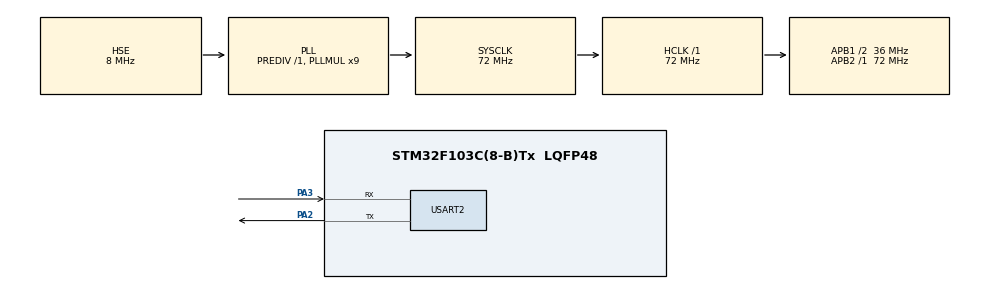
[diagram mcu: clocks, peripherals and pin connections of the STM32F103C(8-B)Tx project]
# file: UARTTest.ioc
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Dma.Request0=USART2_TX
Dma.Request1=USART2_RX
Dma.USART2_RX.1.Direction=DMA_PERIPH_TO_MEMORY
Dma.USART2_RX.1.Instance=DMA1_Channel6
Dma.USART2_RX.1.MemDataAlignment=DMA_MDATAALIGN_BYTE
Dma.USART2_RX.1.MemInc=DMA_MINC_ENABLE
Dma.USART2_RX.1.Mode=DMA_CIRCULAR
Dma.USART2_RX.1.PeriphDataAlignment=DMA_PDATAALIGN_BYTE
Dma.USART2_RX.1.PeriphInc=DMA_PINC_DISABLE
Dma.USART2_RX.1.Priority=DMA_PRIORITY_LOW
Dma.USART2_TX.0.Direction=DMA_MEMORY_TO_PERIPH
Dma.USART2_TX.0.Instance=DMA1_Channel7
Dma.USART2_TX.0.MemDataAlignment=DMA_MDATAALIGN_BYTE
Dma.USART2_TX.0.MemInc=DMA_MINC_ENABLE
Dma.USART2_TX.0.Mode=DMA_NORMAL
Dma.USART2_TX.0.PeriphDataAlignment=DMA_PDATAALIGN_BYTE
Dma.USART2_TX.0.PeriphInc=DMA_PINC_DISABLE
Dma.USART2_TX.0.Priority=DMA_PRIORITY_LOW
Mcu.Family=STM32F1
Mcu.Name=STM32F103C(8-B)Tx
Mcu.Package=LQFP48
NVIC.DMA1_Channel6_IRQn=true\:0\:0\:false\:false\:true\:false\:true
NVIC.DMA1_Channel7_IRQn=true\:0\:0\:false\:false\:true\:false\:true
NVIC.PriorityGroup=NVIC_PRIORITYGROUP_4
NVIC.USART2_IRQn=true\:0\:0\:false\:false\:true\:true\:true
PA13.Mode=Serial_Wire
PA13.Signal=SYS_JTMS-SWDIO
PA14.Mode=Serial_Wire
PA14.Signal=SYS_JTCK-SWCLK
PA2.Mode=Asynchronous
PA2.Signal=USART2_TX
PA3.Mode=Asynchronous
PA3.Signal=USART2_RX
PD0-OSC_IN.Mode=HSE-External-Oscillator
PD0-OSC_IN.Signal=RCC_OSC_IN
PD1-OSC_OUT.Mode=HSE-External-Oscillator
PD1-OSC_OUT.Signal=RCC_OSC_OUT
ProjectManager.HeapSize=0x200
ProjectManager.StackSize=0x400
ProjectManager.TargetToolchain=MDK-ARM V5.27
RCC.AHBFreq_Value=72000000
RCC.APB1CLKDivider=RCC_HCLK_DIV2
RCC.APB1Freq_Value=36000000
RCC.APB1TimFreq_Value=72000000
RCC.APB2Freq_Value=72000000
RCC.APB2TimFreq_Value=72000000
RCC.HCLKFreq_Value=72000000
RCC.PLLMUL=RCC_PLL_MUL9
RCC.PLLSourceVirtual=RCC_PLLSOURCE_HSE
RCC.SYSCLKFreq_VALUE=72000000
RCC.SYSCLKSource=RCC_SYSCLKSOURCE_PLLCLK
RCC.USBFreq_Value=72000000
USART2.VirtualMode=VM_ASYNC
board=custom

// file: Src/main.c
/* USER CODE BEGIN Header */
/**
  ******************************************************************************
  * @file           : main.c
  * @brief          : Main program body
  ******************************************************************************
  * @attention
  *
  * <h2><center>&copy; Copyright (c) 2020 STMicroelectronics.
  * All rights reserved.</center></h2>
  *
  * This software component is licensed by ST under BSD 3-Clause license,
  * the "License"; You may not use this file except in compliance with the
  * License. You may obtain a copy of the License at:
  *                        opensource.org/licenses/BSD-3-Clause
  *
  ******************************************************************************
  */
/* USER CODE END Header */

#include "main.h"
#include "dma.h"
#include "usart.h"
#include "gpio.h"

void SystemClock_Config(void);

/* USER CODE BEGIN 0 */
#define BUFFER_SIZE 200
uint8_t Buffer[BUFFER_SIZE];
volatile uint32_t BufPtrIn = 0, BufPtrOut = 0;

//void HAL_UART_RxCpltCallback(UART_HandleTypeDef *huart)
//{
//	if (huart == &huart2)
//	{
//		BufPtrIn++;
//		if (BufPtrIn == BUFFER_SIZE)
//			BufPtrIn = 0;
//		HAL_UART_Receive_IT(&huart2, &Buffer[BufPtrIn], 1);
//	}
//}

void HAL_SYSTICK_Callback(void)
{
	BufPtrIn = BUFFER_SIZE - huart2.hdmarx->Instance->CNDTR;

	if (HAL_GetTick() % 5 != 0)
		return;

	uint32_t buffsize;

	if (BufPtrOut != BufPtrIn)
	{
		if (BufPtrOut > BufPtrIn) // Rollback
			buffsize = BUFFER_SIZE - BufPtrOut;
		else
			buffsize = BufPtrIn - BufPtrOut;

//		if (HAL_UART_Transmit_IT(&huart2, &Buffer[BufPtrOut], buffsize) == HAL_OK)
		if (HAL_UART_Transmit_DMA(&huart2, &Buffer[BufPtrOut], buffsize) == HAL_OK)
		{
			BufPtrOut += buffsize;
			if (BufPtrOut == BUFFER_SIZE)
				BufPtrOut = 0;
		}
	}
}

#include "stdio.h"
int fputc(int ch, FILE* f)
{
	HAL_UART_Transmit(&huart2, (uint8_t *)&ch, 1, 100);
	return ch;
}
/* USER CODE END 0 */

int main(void)
{

  /* MCU Configuration--------------------------------------------------------*/

  /* Reset of all peripherals, Initializes the Flash interface and the Systick. */
  HAL_Init();

  /* Configure the system clock */
  SystemClock_Config();

  /* Initialize all configured peripherals */
  MX_GPIO_Init();
  MX_DMA_Init();
  MX_USART2_UART_Init();
  /* USER CODE BEGIN 2 */
//	HAL_UART_Receive_IT(&huart2, Buffer, 1); // Buffer = &Buffer[0]
	HAL_UART_Receive_DMA(&huart2, Buffer, BUFFER_SIZE);
  /* USER CODE END 2 */

  /* Infinite loop */
  /* USER CODE BEGIN WHILE */
  while (1)
  {
//		HAL_UART_Transmit_IT(&huart2, (uint8_t *)"Hello\r\n", 7);
//		HAL_Delay(500);

//		printf("Hello World\r\n");
//		HAL_Delay(500);

//		if (HAL_UART_Receive(&huart2, Buffer, 1, 100) == HAL_OK)
//			HAL_UART_Transmit(&huart2, Buffer, 1, 100);

//		HAL_UART_Transmit(&huart2, (uint8_t *)"Hello\r\n", 7, 100);
//		HAL_Delay(500);

    /* USER CODE END WHILE */

  }
}

void SystemClock_Config(void)
{
  RCC_OscInitTypeDef RCC_OscInitStruct = {0};
  RCC_ClkInitTypeDef RCC_ClkInitStruct = {0};

  /** Initializes the CPU, AHB and APB busses clocks
  */
  RCC_OscInitStruct.OscillatorType = RCC_OSCILLATORTYPE_HSE;
  RCC_OscInitStruct.HSEState = RCC_HSE_ON;
  RCC_OscInitStruct.HSEPredivValue = RCC_HSE_PREDIV_DIV1;
  RCC_OscInitStruct.HSIState = RCC_HSI_ON;
  RCC_OscInitStruct.PLL.PLLState = RCC_PLL_ON;
  RCC_OscInitStruct.PLL.PLLSource = RCC_PLLSOURCE_HSE;
  RCC_OscInitStruct.PLL.PLLMUL = RCC_PLL_MUL9;
  if (HAL_RCC_OscConfig(&RCC_OscInitStruct) != HAL_OK)
  {
    Error_Handler();
  }
  /** Initializes the CPU, AHB and APB busses clocks
  */
  RCC_ClkInitStruct.ClockType = RCC_CLOCKTYPE_HCLK|RCC_CLOCKTYPE_SYSCLK
                              |RCC_CLOCKTYPE_PCLK1|RCC_CLOCKTYPE_PCLK2;
  RCC_ClkInitStruct.SYSCLKSource = RCC_SYSCLKSOURCE_PLLCLK;
  RCC_ClkInitStruct.AHBCLKDivider = RCC_SYSCLK_DIV1;
  RCC_ClkInitStruct.APB1CLKDivider = RCC_HCLK_DIV2;
  RCC_ClkInitStruct.APB2CLKDivider = RCC_HCLK_DIV1;

  if (HAL_RCC_ClockConfig(&RCC_ClkInitStruct, FLASH_LATENCY_2) != HAL_OK)
  {
    Error_Handler();
  }
}

void Error_Handler(void)
{
}

/************************ (C) COPYRIGHT STMicroelectronics *****END OF FILE****/
